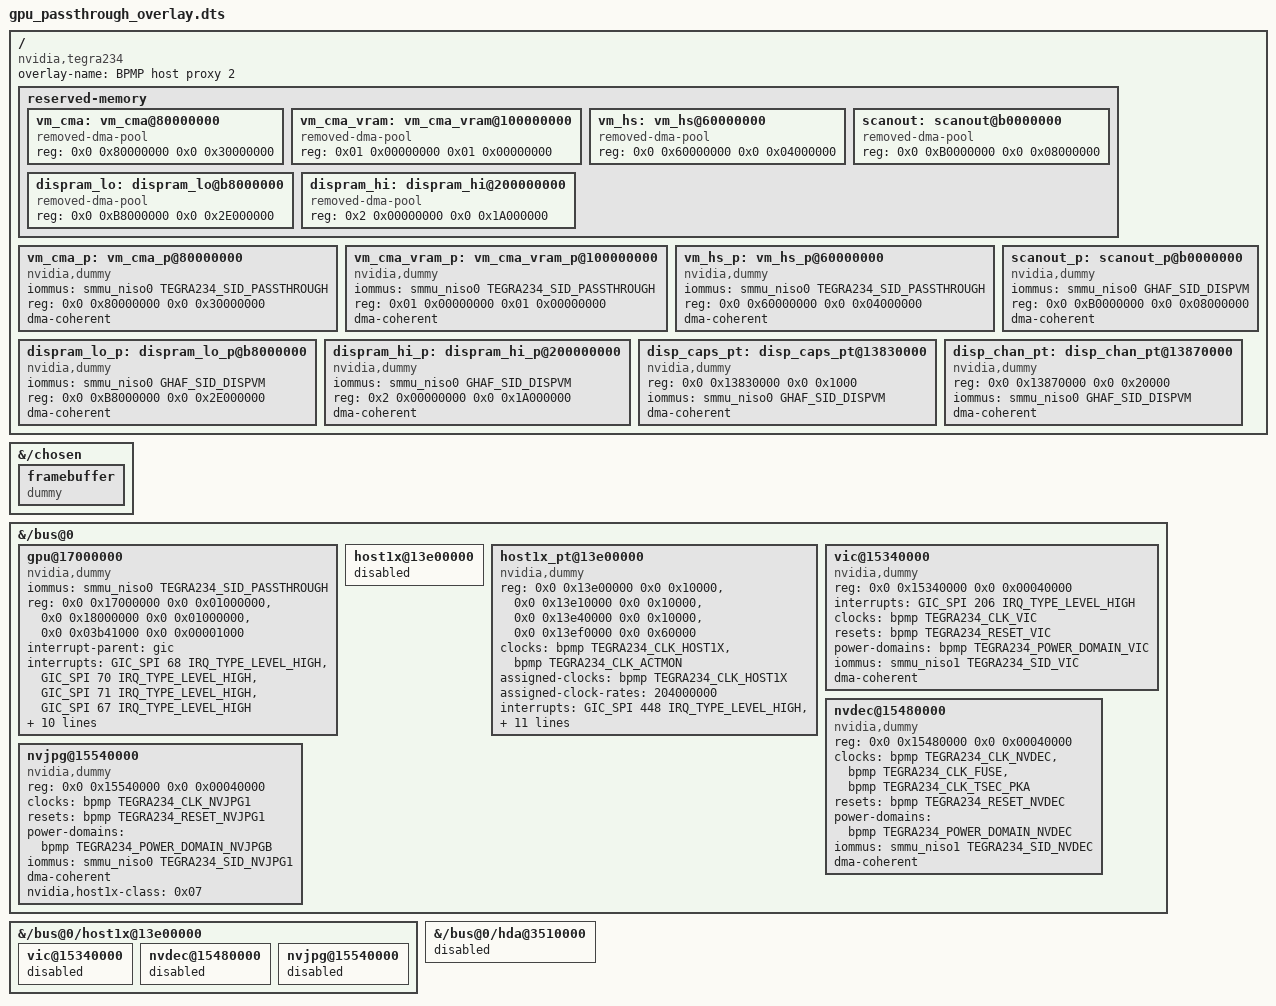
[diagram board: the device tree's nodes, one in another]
/*
 * Copyright 2022-2024 TII (SSRC) and the Ghaf contributors
 * SPDX-License-Identifier: CC-BY-SA-4.0
 */

/dts-v1/;
/plugin/;

#include <dt-bindings/clock/tegra234-clock.h>
#include <dt-bindings/reset/tegra234-reset.h>
#include <dt-bindings/power/tegra234-powergate.h>
#include <dt-bindings/memory/tegra234-mc.h>
#include <dt-bindings/interrupt-controller/irq.h>
#include <dt-bindings/interrupt-controller/arm-gic.h>

/*
 * StreamID for the disp-vm-owned wrapper nodes. Disjoint SMMU group from the
 * GPU: 0x7d is unassigned on T234 (SIDs jump 0x72 -> 0x7f in tegra234-mc.h) and
 * != TEGRA234_SID_PASSTHROUGH (0x7f), so gpu-vm and disp-vm never share a stream.
 */
#define GHAF_SID_DISPVM 0x7d

/ {
    overlay-name = "BPMP host proxy 2";
    compatible = "nvidia,tegra234";
    
    fragment@0 {
        target-path = "/";
        __overlay__ {
            reserved-memory {
                // Reserved CMA for VM CMA
                vm_cma: vm_cma@80000000 {
                    compatible = "removed-dma-pool";
                    reg = <0x0 0x80000000 0x0 0x30000000>;				// 768MB
                    status = "okay";
                };
                // Reserved CMA for VM GPU VRAM
                vm_cma_vram: vm_cma_vram@100000000 {
                    compatible = "removed-dma-pool";
                    reg = <0x01 0x00000000 0x01 0x00000000>;            // 4GB
                };
                // Reserved CMA for VM host1x sem-syncpt-shim
                vm_hs: vm_hs@60000000 {
                    compatible = "removed-dma-pool";
                    reg = <0x0 0x60000000 0x0 0x04000000>;				// host1x 64MB sem-syncpt-shim
                    status = "okay";
                };
                // 1:1 scanout carveout (GPA=HPA) for the guest nvdisplay
                // surface; host-owned DCE R5 DMAs it at the same PA (scanout_p).
                scanout: scanout@b0000000 {
                    compatible = "removed-dma-pool";
                    reg = <0x0 0xB0000000 0x0 0x08000000>;				// 128MB
                    status = "okay";
                };
                // disp-vm guest RAM = SPLIT carveout (1:1 GPA=HPA). LOW bank:
                // kernel/initrd + 672MB RAM + 64MB CMA (QEMU -M virt loads kernel
                // low; all-high -> init killed; <672MB -> init SIGSEGV). HIGH bank
                // (>4GB): GPU-style carveouts. DMA32 hole 0xe6000000..0x100000000
                // (416MB) left to host so 14100000.pcie MSI page allocates (WLAN/net-vm).
                dispram_lo: dispram_lo@b8000000 {
                    compatible = "removed-dma-pool";
                    reg = <0x0 0xB8000000 0x0 0x2E000000>;				// 736MB (0xb8..0xe6)
                    status = "okay";
                };
                dispram_hi: dispram_hi@200000000 {
                    compatible = "removed-dma-pool";
                    reg = <0x2 0x00000000 0x0 0x1A000000>;				// 416MB @ 8GB (0x200..0x21a)
                    status = "okay";
                };
            };

            // Bind the VM reserved-memory regions to a dummy driver so they can
            // attach to vfio-platform.
            vm_cma_p: vm_cma_p@80000000 {
                compatible = "nvidia,dummy";
                iommus = <&smmu_niso0 TEGRA234_SID_PASSTHROUGH>;
                reg = <0x0 0x80000000 0x0 0x30000000>;              	// 768MB
                dma-coherent;
                status = "okay";
            };

            vm_cma_vram_p: vm_cma_vram_p@100000000 {
                compatible = "nvidia,dummy";
                iommus = <&smmu_niso0 TEGRA234_SID_PASSTHROUGH>;
                reg = <0x01 0x00000000 0x01 0x00000000>;                // 4GB
                dma-coherent;
                status = "okay";
            };

            vm_hs_p: vm_hs_p@60000000 {
                compatible = "nvidia,dummy";
                iommus = <&smmu_niso0 TEGRA234_SID_PASSTHROUGH>;
                reg = <0x0 0x60000000 0x0 0x04000000>;				// host1x sem-syncpt-shimZ
                dma-coherent;
                status = "okay";
            };

            // Bind scanout to vfio-platform so QEMU maps it 1:1
            // (mmio-base=0xb0000000) into the guest for the nvdisplay scanout.
            scanout_p: scanout_p@b0000000 {
                compatible = "nvidia,dummy";
                iommus = <&smmu_niso0 GHAF_SID_DISPVM> /* concurrent: distinct group from GPU, DMA-less wrapper */;
                reg = <0x0 0xB0000000 0x0 0x08000000>;				// 128MB
                dma-coherent;
                status = "okay";
            };
            // disp-vm RAM carveout, 1:1 vfio (mmio-base=0x200000000).
            // GHAF_SID_DISPVM -> same IOMMU group as the other disp-vm wrappers,
            // disjoint from GPU.
            dispram_lo_p: dispram_lo_p@b8000000 {
                compatible = "nvidia,dummy";
                iommus = <&smmu_niso0 GHAF_SID_DISPVM>;
                reg = <0x0 0xB8000000 0x0 0x2E000000>;				// 736MB
                dma-coherent;
                status = "okay";
            };
            dispram_hi_p: dispram_hi_p@200000000 {
                compatible = "nvidia,dummy";
                iommus = <&smmu_niso0 GHAF_SID_DISPVM>;
                reg = <0x2 0x00000000 0x0 0x1A000000>;				// 416MB @ 8GB
                dma-coherent;
                status = "okay";
            };
        };
    };

    // Passthrough devices: set dummy driver + iommus + dma-coherent.
    // fragment@1 (display@13800000 dummy override) removed: display NOT passed
    // through; host keeps the REAL display node (stock compatible + SID_NVDISPLAY).
    // Rewriting it to dummy halts the host DCE R5 at dce_ss_set. Guest reaches the
    // panel via the DCE host-proxy.

    // fragment@2 (dce@d800000 dummy override) removed: DCE NOT passed through.
    // Host keeps the REAL dce node so host tegra-dce owns the R5; guest drives the
    // panel via the DCE host-proxy.

    // Dummy framebuffer compatible so UEFI doesn't enable the host framebuffer.
    fragment@3 {
        target-path = "/chosen";
        __overlay__ {
            framebuffer {
                compatible = "dummy";
                status = "okay";
            };
        };
    };


    fragment@4 {
        target-path = "/bus@0";
        __overlay__ {
            gpu@17000000 {
                compatible = "nvidia,dummy";
                iommus = <&smmu_niso0 TEGRA234_SID_PASSTHROUGH>;
                reg = <0x0 0x17000000 0x0 0x01000000>,
                    <0x0 0x18000000 0x0 0x01000000>,
                    <0x0 0x03b41000 0x0 0x00001000>;
                interrupt-parent = <&gic>;
                interrupts = <GIC_SPI 68 IRQ_TYPE_LEVEL_HIGH>,
                        <GIC_SPI 70 IRQ_TYPE_LEVEL_HIGH>,
                        <GIC_SPI 71 IRQ_TYPE_LEVEL_HIGH>,
                        <GIC_SPI 67 IRQ_TYPE_LEVEL_HIGH>;
                interrupt-names = "stall0", "stall1", "stall2", "nonstall";
                power-domains = <&bpmp TEGRA234_POWER_DOMAIN_GPU>;
                interconnects = <&mc TEGRA234_MEMORY_CLIENT_NVL1R &emc>,
                        <&mc TEGRA234_MEMORY_CLIENT_NVL1W &emc>;
                interconnect-names = "dma-mem", "write";
                clocks = <&bpmp TEGRA234_CLK_GPUSYS>,
                    <&bpmp TEGRA234_CLK_GPC0CLK>,
                    <&bpmp TEGRA234_CLK_GPC1CLK>;
                clock-names = "sysclk", "gpc0clk", "gpc1clk";
                resets = <&bpmp TEGRA234_RESET_GPU>;
                dma-coherent;
                nvidia,bpmp = <&bpmp>;
                status = "okay";
            };
        };
    };

    // Disable host1x; replaced by host1x_pt@13e00000 below.
    fragment@5 {
        target-path = "/bus@0";
        __overlay__ {
            host1x@13e00000 {
                status = "disabled";
            };
        };
    };

    // Disable these devices to use the ones created later.
    fragment@6 {
        target-path = "/bus@0/host1x@13e00000";
        __overlay__ {
            vic@15340000  {
                status = "disabled";
            };
            nvdec@15480000 {
                status = "disabled";
            };
            nvjpg@15540000 {
                status = "disabled";
            };
        };
    };
    
    // Recreated from scratch: DT can't remove properties, and some originals must go.
    fragment@7 {
        target-path = "/bus@0";
        __overlay__ {
            host1x_pt@13e00000 {
                compatible = "nvidia,dummy";
                reg = <0x0 0x13e00000 0x0 0x10000>,
                    <0x0 0x13e10000 0x0 0x10000>,
                    <0x0 0x13e40000 0x0 0x10000>,
                    <0x0 0x13ef0000 0x0 0x60000>;
                reg-names = "common", "hypervisor", "vm", "actmon";

                clocks = <&bpmp TEGRA234_CLK_HOST1X>,
                    <&bpmp TEGRA234_CLK_ACTMON>;
                clock-names = "host1x", "actmon";
                assigned-clocks = <&bpmp TEGRA234_CLK_HOST1X>;
                assigned-clock-rates = <204000000>;

                interrupts = <GIC_SPI 448 IRQ_TYPE_LEVEL_HIGH>,
                        <GIC_SPI 449 IRQ_TYPE_LEVEL_HIGH>,
                        <GIC_SPI 450 IRQ_TYPE_LEVEL_HIGH>,
                        <GIC_SPI 451 IRQ_TYPE_LEVEL_HIGH>,
                        <GIC_SPI 452 IRQ_TYPE_LEVEL_HIGH>,
                        <GIC_SPI 453 IRQ_TYPE_LEVEL_HIGH>,
                        <GIC_SPI 454 IRQ_TYPE_LEVEL_HIGH>,
                        <GIC_SPI 455 IRQ_TYPE_LEVEL_HIGH>,
                        <GIC_SPI 263 IRQ_TYPE_LEVEL_HIGH>;
                interrupt-names = "syncpt0", "syncpt1", "syncpt2", "syncpt3", "syncpt4",
                        "syncpt5", "syncpt6", "syncpt7", "host1x";
                #address-cells = <2>;
                #size-cells = <2>;
                iommus = <&smmu_niso1 TEGRA234_SID_HOST1X>;
                dma-coherent;

                interrupt-parent = <&gic>;

                ranges = <0x0 0x14800000 0x0 0x14800000 0x0 0x02000000>,
                    <0x0 0x24700000 0x0 0x24700000 0x0 0x00080000>;

                status = "okay";
            };
		
		vic@15340000 {
			compatible = "nvidia,dummy";
			reg = <0x0 0x15340000 0x0 0x00040000>;
			interrupts = <GIC_SPI 206 IRQ_TYPE_LEVEL_HIGH>;
			clocks = <&bpmp TEGRA234_CLK_VIC>;
			clock-names = "vic";
			resets = <&bpmp TEGRA234_RESET_VIC>;
			reset-names = "vic";
			power-domains = <&bpmp TEGRA234_POWER_DOMAIN_VIC>;
			iommus = <&smmu_niso1 TEGRA234_SID_VIC>;
			dma-coherent;
			status = "okay";
		};

        nvdec@15480000 {
                compatible = "nvidia,dummy";
                reg = <0x0 0x15480000 0x0 0x00040000>;
                clocks = <&bpmp TEGRA234_CLK_NVDEC>,
                        <&bpmp TEGRA234_CLK_FUSE>,
                        <&bpmp TEGRA234_CLK_TSEC_PKA>;
                clock-names = "nvdec", "fuse", "tsec_pka";
                resets = <&bpmp TEGRA234_RESET_NVDEC>;
                reset-names = "nvdec";
                power-domains = <&bpmp TEGRA234_POWER_DOMAIN_NVDEC>;
                iommus = <&smmu_niso1 TEGRA234_SID_NVDEC>;
                dma-coherent;
                status = "okay";
            };

        nvjpg@15540000 {
                compatible = "nvidia,dummy";
                reg = <0x0 0x15540000 0x0 0x00040000>;
                clocks = <&bpmp TEGRA234_CLK_NVJPG1>;
                clock-names = "nvjpg";
                resets = <&bpmp TEGRA234_RESET_NVJPG1>;
                reset-names = "nvjpg";

                power-domains = <&bpmp TEGRA234_POWER_DOMAIN_NVJPGB>;
                // interconnects = <&mc TEGRA234_MEMORY_CLIENT_NVJPG1SRD &emc>,
                // 		<&mc TEGRA234_MEMORY_CLIENT_NVJPG1SWR &emc>;
                // interconnect-names = "dma-mem", "write";
                iommus = <&smmu_niso0 TEGRA234_SID_NVJPG1>;
                dma-coherent;

                nvidia,host1x-class = <0x07>;
                status = "okay";
            };
        };
    };

    // Disabled to avoid a cbb-fabric PWRDOWN_ERR fault (tegra234-cbb.c
    // tegra234_cbb_isr WARNING): CCPLEX read of 0x351804c, Slave_Id 0x37.
    fragment@8 {
        target-path = "/bus@0/hda@3510000";
        __overlay__ {
            status = "disabled";
        };
    };

    // Keyhole: expose ONLY the 4KB RO EVO display-capabilities strap page
    // (display + 0x30000 = 0x13830000). Guest nvdisplay reads caps here
    // (NVC673_DISP_CAPABILITIES); unbacked -> nvidia_modeset takes a synchronous
    // external abort. Not the whole display aperture (full passthrough kills the
    // host DCE R5). Straps are RO, outside DCE's live control plane, so dual-mapping
    // alongside the R5 is safe. Isolated SID_PASSTHROUGH; node does no DMA so SID is inert.
    fragment@9 {
        target-path = "/";
        __overlay__ {
            disp_caps_pt: disp_caps_pt@13830000 {
                compatible = "nvidia,dummy";
                reg = <0x0 0x13830000 0x0 0x1000>;
                iommus = <&smmu_niso0 GHAF_SID_DISPVM> /* concurrent: distinct group */;
                dma-coherent;
                status = "okay";
            };
        };
    };

    // Second keyhole: EVO channel DOORBELL registers (PUT/GET). Guest nvkms writes
    // PUT to tell the DCE R5 to fetch the pushbuffer. Unbacked -> PUT never reaches
    // HW, R5 never fetches, GET stays 0 (nvidia-modeset: waiting for GPU progress).
    // CPU-RM user doorbells (guest IS the CPU RM); R5 owns core/control. Map the
    // whole region 0x13870000..0x1388ffff (core + windows + cursor/IMM). Isolated
    // SID_PASSTHROUGH, no reset -> R5-safe.
    fragment@10 {
        target-path = "/";
        __overlay__ {
            disp_chan_pt: disp_chan_pt@13870000 {
                compatible = "nvidia,dummy";
                reg = <0x0 0x13870000 0x0 0x20000>;
                iommus = <&smmu_niso0 GHAF_SID_DISPVM> /* concurrent: distinct group */;
                dma-coherent;
                status = "okay";
            };
        };
    };

    // No dpaux0/MIPI_CAL keyhole: inert on T234D -- CPU-side RM never instantiates
    // OBJDPAUX, EDID/AUX go RmControl -> DCE-RPC (R5 owns the pads).
};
